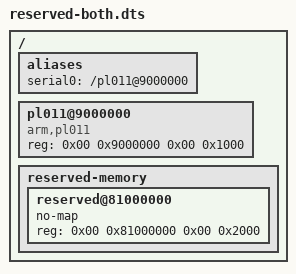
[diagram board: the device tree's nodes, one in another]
/dts-v1/;

/memreserve/ 0x0000000080000000 0x0000000000001000;

/ {
	#address-cells = <0x02>;
	#size-cells = <0x02>;

	aliases {
		serial0 = "/pl011@9000000";
	};

	pl011@9000000 {
		compatible = "arm,pl011", "arm,primecell";
		reg = <0x00 0x9000000 0x00 0x1000>;
	};

	reserved-memory {
		#address-cells = <0x02>;
		#size-cells = <0x02>;
		ranges;

		reserved@81000000 {
			no-map;
			reg = <0x00 0x81000000 0x00 0x2000>;
		};
	};
};
